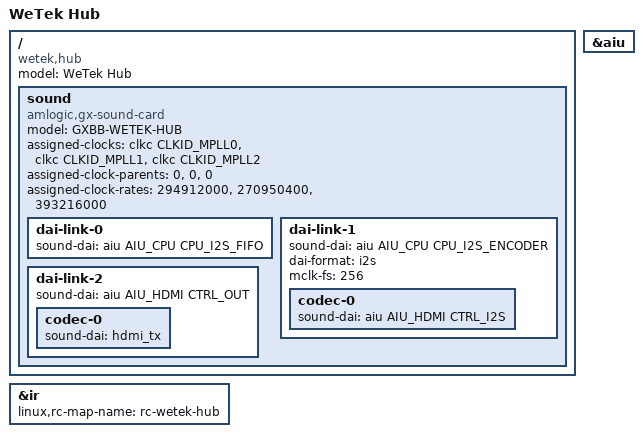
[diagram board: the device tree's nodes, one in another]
// SPDX-License-Identifier: (GPL-2.0+ OR MIT)
/*
 * Copyright (c) 2016 BayLibre, Inc.
 * Author: Neil Armstrong <narmstrong@baylibre.com>
 */

/dts-v1/;

#include "meson-gxbb-wetek.dtsi"
#include <dt-bindings/sound/meson-aiu.h>

/ {
	compatible = "wetek,hub", "amlogic,meson-gxbb";
	model = "WeTek Hub";

	sound {
		compatible = "amlogic,gx-sound-card";
		model = "GXBB-WETEK-HUB";
		assigned-clocks = <&clkc CLKID_MPLL0>,
				  <&clkc CLKID_MPLL1>,
				  <&clkc CLKID_MPLL2>;
		assigned-clock-parents = <0>, <0>, <0>;
		assigned-clock-rates = <294912000>,
				       <270950400>,
				       <393216000>;
		status = "okay";

		dai-link-0 {
			sound-dai = <&aiu AIU_CPU CPU_I2S_FIFO>;
		};

		dai-link-1 {
			sound-dai = <&aiu AIU_CPU CPU_I2S_ENCODER>;
			dai-format = "i2s";
			mclk-fs = <256>;

			codec-0 {
				sound-dai = <&aiu AIU_HDMI CTRL_I2S>;
			};
		};

		dai-link-2 {
			sound-dai = <&aiu AIU_HDMI CTRL_OUT>;

			codec-0 {
				sound-dai = <&hdmi_tx>;
			};
		};
	};
};

&aiu {
	status = "okay";
};

&ir {
	linux,rc-map-name = "rc-wetek-hub";
};
